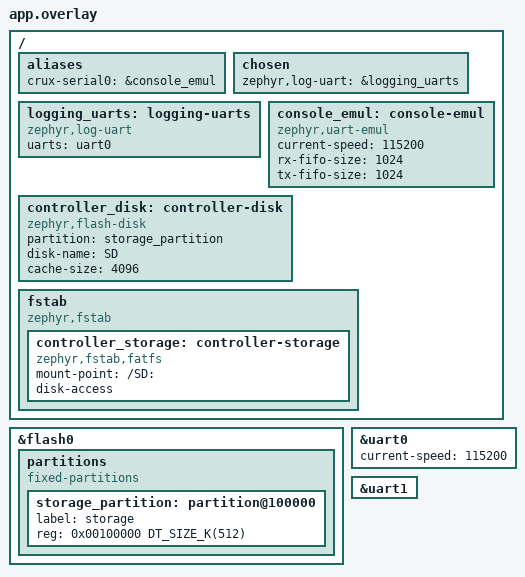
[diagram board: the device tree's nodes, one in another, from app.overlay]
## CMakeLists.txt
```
# SPDX-License-Identifier: Apache-2.0

# The base image on native_sim for a person at the host: HTTPS management on the host's loopback
# address, Crux Logging on standard output and the Crux serial console on a pseudo-terminal
# (docs/native-sim-interactive.md). It is built as a product builds the base image: the framework is
# the Zephyr module of this repository, turned on by CONFIG_CRUX_CONTROLLER_FRAMEWORK, and this file
# names no source or include directory of the framework. It is for development only. The entropy is
# the simulator's test source, so a key made here protects nothing, and the build refuses any other
# board; a board image of the framework includes framework/management/entropy.cmake, which refuses a
# test source.

cmake_minimum_required(VERSION 3.20.0)
find_package(Zephyr REQUIRED HINTS $ENV{ZEPHYR_BASE})
project(controller_framework_interactive_native_sim LANGUAGES C)

if(NOT CONFIG_BOARD_NATIVE_SIM OR NOT CONFIG_FAKE_ENTROPY_NATIVE_SIM)
    message(FATAL_ERROR "The interactive configuration is for native_sim only: its entropy source is a test source")
endif()
if(NOT CONFIG_CRUX_WEB_BIND_ADDRESS STREQUAL "127.0.0.1")
    message(FATAL_ERROR "The interactive configuration listens on the host's loopback address only: "
                        "CONFIG_CRUX_WEB_BIND_ADDRESS must be \"127.0.0.1\"")
endif()
if(NOT CONFIG_CRUX_CONTROLLER_FRAMEWORK OR NOT CONFIG_CRUX_CONTROLLER_FRAMEWORK_MANAGEMENT
   OR NOT CONFIG_CRUX_CONTROLLER_FRAMEWORK_CLI_SERIAL)
    message(FATAL_ERROR "The interactive configuration needs the framework with web management and the serial command line")
endif()

# Interim, development only: native_sim's offload reports a client's FIN so that a close without a TLS
# close_notify does not spin the web server (nsos_rdhup.cmake, docs/native-sim-interactive.md).
include(${CMAKE_CURRENT_LIST_DIR}/nsos_rdhup.cmake)

target_sources(app PRIVATE src/interactive.c)
target_link_libraries(app PRIVATE controller::framework)
controller_framework_image()
```

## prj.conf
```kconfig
# The base image on native_sim for a person at the host (docs/native-sim-interactive.md). The values
# are those of the base scenario (tests/framework/base/prj.conf) with these changes:
#   - the network is the host's, through native_sim's offloaded sockets, in place of Zephyr's
#     loopback interface, and management listens on the host's 127.0.0.1 port 8443;
#   - Crux Logging writes to native_sim's first PTY UART, which is the program's standard output;
#   - the store is a FAT volume on the flash simulator, which keeps its contents in a host file;
#   - no Ztest and no emulated log UART;
#   - the main thread runs the start function below the supervisor, as app/conf/base.conf sets, and a
#     restart request restarts the program. There is no retained region.
# For development only: the entropy is the simulator's test source.
CONFIG_CRUX_CONTROLLER_FRAMEWORK=y
CONFIG_SNTP=y
# No SNTP server answers there, so time synchronisation starts and its queries fail; nothing leaves
# the host.
CONFIG_CRUX_CONTROLLER_TIME_SERVER="127.0.0.1"

# Health supervision in the production watchdog configuration of the base image: no task watchdog
# hardware fallback, no start without a watchdog, no fault injection. native_sim has no watchdog
# behind the alias crux-watchdog0 here, so the watchdog is not armed and the controller is degraded.
# There is no retained region, so the boot counter lives in RAM. A restart request, from the command
# line or from the supervisor, restarts the program (CONFIG_NATIVE_SIM_REBOOT).
CONFIG_TASK_WDT=y
CONFIG_TASK_WDT_HW_FALLBACK=n
CONFIG_CRUX_REBOOT=y
CONFIG_NATIVE_SIM_REBOOT=y
CONFIG_MAIN_THREAD_PRIORITY=8

# The Crux serial console runs on an emulated UART, the only kind that Crux Serial accepts on
# native_sim; src/interactive.c bridges it to the second PTY UART.
CONFIG_CRUX_SERIAL=y
CONFIG_CRUX_CLI=y
CONFIG_CRUX_CLI_CONSOLE=y
CONFIG_CRUX_CLI_CONSOLE_PRIORITY=11
CONFIG_UART_INTERRUPT_DRIVEN=y
CONFIG_UART_USE_RUNTIME_CONFIGURE=y
CONFIG_EMUL=y
CONFIG_UART_EMUL=y

CONFIG_STD_C17=y
# The web adapter refuses the external libc of native_sim, as in the base scenario.
CONFIG_PICOLIBC=y
CONFIG_MAIN_STACK_SIZE=32768
CONFIG_HEAP_MEM_POOL_SIZE=32768

# The Mbed TLS profile of app/conf/base.conf, with the heap of the base image (no TLS client runs in
# this process).
CONFIG_MBEDTLS=y
CONFIG_MBEDTLS_PSA_CRYPTO_C=y
CONFIG_PSA_CRYPTO_PROVIDER_MBEDTLS=y
CONFIG_MBEDTLS_ENABLE_HEAP=y
CONFIG_MBEDTLS_HEAP_SIZE=120000
CONFIG_MBEDTLS_SSL_IN_CONTENT_LEN=16384
CONFIG_MBEDTLS_SSL_OUT_CONTENT_LEN=16384
CONFIG_MBEDTLS_SSL_PROTO_TLS1_2=y
CONFIG_MBEDTLS_SSL_PROTO_TLS1_3=y
CONFIG_MBEDTLS_SSL_TLS1_3_KEY_EXCHANGE_MODE_EPHEMERAL_ENABLED=y
CONFIG_MBEDTLS_KEY_EXCHANGE_ECDHE_ECDSA_ENABLED=y
CONFIG_MBEDTLS_CIPHERSUITE_TLS_ECDHE_ECDSA_WITH_AES_128_GCM_SHA256=y
CONFIG_MBEDTLS_CIPHERSUITE_TLS1_3_AES_128_GCM_SHA256=y
CONFIG_PSA_WANT_ALG_SHA_256=y
CONFIG_PSA_WANT_ECC_SECP_R1_256=y
CONFIG_PSA_WANT_ALG_ECDSA=y
CONFIG_PSA_WANT_ALG_ECDH=y
CONFIG_PSA_WANT_ALG_GCM=y
CONFIG_PSA_WANT_KEY_TYPE_AES=y
CONFIG_PSA_WANT_ALG_HMAC=y
CONFIG_PSA_WANT_KEY_TYPE_HMAC=y
CONFIG_PSA_WANT_ALG_HKDF=y
CONFIG_PSA_WANT_ALG_PBKDF2_HMAC=y
CONFIG_PSA_WANT_ALG_TLS12_PRF=y
CONFIG_PSA_WANT_KEY_TYPE_ECC_PUBLIC_KEY=y
CONFIG_PSA_WANT_KEY_TYPE_ECC_KEY_PAIR_IMPORT=y
CONFIG_PSA_WANT_KEY_TYPE_ECC_KEY_PAIR_EXPORT=y
CONFIG_PSA_WANT_KEY_TYPE_ECC_KEY_PAIR_GENERATE=y
CONFIG_PSA_WANT_KEY_TYPE_ECC_KEY_PAIR_DERIVE=y
CONFIG_MBEDTLS_PK_WRITE_C=y
CONFIG_CRUX_PSA_THREADING=y

CONFIG_CRUX_ACCESS=y
CONFIG_CRUX_CONFIG_SERVICE=y
CONFIG_CRUX_MGMT_STATUS=y
CONFIG_CRUX_TLS_CERTIFICATE=y
CONFIG_CRUX_WEB=y
CONFIG_CRUX_WEB_SESSION=y
CONFIG_CRUX_WEB_MANAGEMENT=y
CONFIG_CRUX_SYSTEM=y
CONFIG_CRUX_NETIF=y
CONFIG_WATCHDOG=y
CONFIG_HWINFO=y
CONFIG_REBOOT=y

# The host's loopback address only, and a port that needs no privilege on the host.
CONFIG_CRUX_WEB_PORT=8443
CONFIG_CRUX_WEB_BIND_ADDRESS="127.0.0.1"
CONFIG_CRUX_WEB_BACKLOG=4
CONFIG_HTTP_SERVER_MAX_CLIENTS=3
CONFIG_HTTP_SERVER_STACK_SIZE=16384
CONFIG_CRUX_WEB_SESSION_WORKER_PRIORITY=11
CONFIG_CRUX_WEB_MANAGEMENT_WORKER_PRIORITY=11
CONFIG_CRUX_SECURITY_EVENT_DRAIN_PRIORITY=11

# The simulator's fake entropy source: test-only, so nothing made here is a secret.
# scripts/run-native-sim.sh seeds it from the host for each run.
CONFIG_ENTROPY_GENERATOR=y

# Crux File on a flash disk of the flash simulator, which native_sim keeps in a host file (option
# --flash), so accounts, settings, the key and the certificate outlive a restart. The zone formats
# the blank disk at the first start.
CONFIG_FILE_SYSTEM=y
CONFIG_FILE_SYSTEM_MKFS=y
CONFIG_FAT_FILESYSTEM_ELM=y
CONFIG_FS_FATFS_LFN=y
CONFIG_FS_FATFS_LFN_MODE_STACK=y
CONFIG_FS_FATFS_MAX_LFN=127
CONFIG_FS_FATFS_MOUNT_MKFS=n
CONFIG_FS_FATFS_REENTRANT=y
CONFIG_FS_FATFS_NUM_FILES=6
CONFIG_DISK_DRIVERS=y
CONFIG_DISK_DRIVER_FLASH=y
CONFIG_CRUX_FILE_FATFS_SIMULATOR=y

# The network: the host's sockets through native_sim's offloaded sockets driver, with Zephyr's TLS
# socket layer on top. No TAP interface and no loopback interface of Zephyr.
CONFIG_NETWORKING=y
CONFIG_NET_IPV4=y
CONFIG_NET_IPV6=n
CONFIG_NET_TCP=y
CONFIG_NET_UDP=y
CONFIG_NET_SOCKETS=y
CONFIG_NET_DRIVERS=y
CONFIG_NET_SOCKETS_OFFLOAD=y
CONFIG_NET_NATIVE_OFFLOADED_SOCKETS=y
CONFIG_ETH_NATIVE_TAP=n
CONFIG_NET_SOCKETS_SOCKOPT_TLS=y
CONFIG_TLS_CREDENTIALS=y
CONFIG_TLS_MAX_CREDENTIALS_NUMBER=4
CONFIG_NET_SOCKETS_TLS_MAX_CONTEXTS=6
CONFIG_ZVFS_OPEN_MAX=48
CONFIG_ZVFS_POLL_MAX=24
CONFIG_ZVFS_EVENTFD=y
CONFIG_NET_MAX_CONTEXTS=32
CONFIG_NET_MAX_CONN=32

# Crux Logging on native_sim's console UART, as Crux's logging contract describes it, connected to
# the program's standard output.
CONFIG_CRUX_LOGGING=y
CONFIG_SERIAL=y
CONFIG_CONSOLE=y
CONFIG_UART_CONSOLE=y
CONFIG_UART_NATIVE_PTY_0_ON_STDINOUT=y
CONFIG_STDOUT_CONSOLE=n
CONFIG_EARLY_CONSOLE=n
CONFIG_CONSOLE_HANDLER=n
CONFIG_CONSOLE_SUBSYS=n
CONFIG_LOG=y
CONFIG_LOG_MODE_DEFERRED=y
CONFIG_LOG_MODE_OVERFLOW=n
CONFIG_LOG_BLOCK_IN_THREAD=n
CONFIG_LOG_PROCESS_THREAD=y
CONFIG_LOG_PROCESS_THREAD_STACK_SIZE=2048
CONFIG_LOG_PROCESS_THREAD_CUSTOM_PRIORITY=y
CONFIG_LOG_PROCESS_THREAD_PRIORITY=14
CONFIG_LOG_BUFFER_SIZE=8192
CONFIG_LOG_MAX_LEVEL=4
CONFIG_LOG_DEFAULT_LEVEL=0
CONFIG_LOG_RUNTIME_FILTERING=n
CONFIG_LOG_BACKEND_UART=y
CONFIG_LOG_BACKEND_NATIVE_POSIX=n
CONFIG_LOG_BACKEND_UART_ASYNC=n
CONFIG_LOG_PRINTK=y
CONFIG_SHELL_LOG_BACKEND=n
CONFIG_LOG_BACKEND_SHOW_LEVEL=y
CONFIG_LOG_BACKEND_CRLF_NONE=n
CONFIG_BOOT_BANNER=n
CONFIG_THREAD_MONITOR=y
CONFIG_THREAD_NAME=y
# An image with Crux management must not enable the Zephyr shell.
CONFIG_SHELL=n
```

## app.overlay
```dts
/* SPDX-License-Identifier: Apache-2.0 */
/* The devicetree of the interactive configuration (docs/native-sim-interactive.md).
 *
 * - Crux Logging writes to native_sim's console UART, uart0, which prj.conf connects to the
 *   program's standard output (Crux's logging contract names this composition).
 * - The Crux serial console owns an emulated UART through the alias crux-serial0, because Crux
 *   Serial accepts only an emulated UART on native_sim. src/interactive.c bridges it to uart1, a PTY UART
 *   that native_sim connects to a new pseudo-terminal of the host.
 * - The store is a FAT volume on a flash disk of the flash simulator, which native_sim keeps in a
 *   host file. The fstab entry is controller_storage, the name that the composition zone looks up.
 *   The partition and the disk are those of Crux's management composition on native_sim
 *   (tests/native/management_composition/app.overlay at the pinned Crux). */
/delete-node/ &storage_partition;

&flash0 {
    partitions {
        compatible = "fixed-partitions";
        #address-cells = <1>;
        #size-cells = <1>;

        storage_partition: partition@100000 {
            label = "storage";
            reg = <0x00100000 DT_SIZE_K(512)>;
        };
    };
};

&uart0 { current-speed = <115200>; };
&uart1 { status = "okay"; };

/ {
    aliases { crux-serial0 = &console_emul; };
    chosen { zephyr,log-uart = &logging_uarts; };
    logging_uarts: logging-uarts {
        compatible = "zephyr,log-uart";
        uarts = <&uart0>;
    };
    console_emul: console-emul {
        compatible = "zephyr,uart-emul";
        current-speed = <115200>;
        rx-fifo-size = <1024>;
        tx-fifo-size = <1024>;
        status = "okay";
    };

    controller_disk: controller-disk {
        compatible = "zephyr,flash-disk";
        partition = <&storage_partition>;
        disk-name = "SD";
        cache-size = <4096>;
        status = "okay";
    };

    fstab {
        compatible = "zephyr,fstab";
        controller_storage: controller-storage {
            compatible = "zephyr,fstab,fatfs";
            mount-point = "/SD:";
            disk-access;
        };
    };
};
```

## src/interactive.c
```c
/* SPDX-License-Identifier: Apache-2.0 */

/* The base image on native_sim for a person at the host (docs/native-sim-interactive.md): main
 * starts the controller framework as the base image does, and a bridge thread connects the Crux
 * serial console to a pseudo-terminal of the host.
 *
 * The bridge exists because Crux Serial accepts only an emulated UART on native_sim (the
 * BUILD_ASSERT in components/serial/ports/zephyr/serial_binding.c at the pinned Crux), while a
 * person needs a pseudo-terminal. It copies what the person types on the PTY UART uart1 into the
 * receive side of the emulated UART, and what the console writes on the emulated UART to uart1. It
 * polls both, because the PTY UART reads without blocking. Development only: a board image has no
 * bridge, and the console owns its UART there. */

#include <stddef.h>
#include <stdint.h>

#include <controller/framework.h>
#include <zephyr/device.h>
#include <zephyr/drivers/serial/uart_emul.h>
#include <zephyr/drivers/uart.h>
#include <zephyr/kernel.h>
#include <zephyr/sys/printk.h>

#define CONSOLE_EMUL DEVICE_DT_GET(DT_ALIAS(crux_serial0))
#define CONSOLE_PTY DEVICE_DT_GET(DT_NODELABEL(uart1))
#define BRIDGE_POLL_MS 5
#define BRIDGE_CHUNK 64u
#define BRIDGE_STACK 2048
/* Below the console (CONFIG_CRUX_CLI_CONSOLE_PRIORITY) and the web workers, above the log. */
#define BRIDGE_PRIORITY 13

/* Typed bytes into the emulated UART. A full receive FIFO is retried, so a paste is kept. */
static void bridge_typed(void)
{
    uint8_t chunk[BRIDGE_CHUNK];
    unsigned char byte;
    size_t length = 0u;

    while (length < sizeof chunk && uart_poll_in(CONSOLE_PTY, &byte) == 0) {
        chunk[length++] = byte;
    }
    for (size_t done = 0u; done < length;) {
        done += uart_emul_put_rx_data(CONSOLE_EMUL, &chunk[done], length - done);
        if (done < length) {
            k_msleep(BRIDGE_POLL_MS);
        }
    }
}

/* The console's output to the pseudo-terminal. */
static void bridge_written(void)
{
    uint8_t chunk[BRIDGE_CHUNK];
    uint32_t got;

    while ((got = uart_emul_get_tx_data(CONSOLE_EMUL, chunk, sizeof chunk)) > 0u) {
        for (uint32_t i = 0u; i < got; i++) {
            uart_poll_out(CONSOLE_PTY, chunk[i]);
        }
    }
}

static void bridge_run(void *unused1, void *unused2, void *unused3)
{
    ARG_UNUSED(unused1);
    ARG_UNUSED(unused2);
    ARG_UNUSED(unused3);

    if (!device_is_ready(CONSOLE_EMUL) || !device_is_ready(CONSOLE_PTY)) {
        printk("console bridge: a UART is not ready\n");
        return;
    }
    for (;;) {
        bridge_typed();
        bridge_written();
        k_msleep(BRIDGE_POLL_MS);
    }
}

K_THREAD_DEFINE(console_bridge, BRIDGE_STACK, bridge_run, NULL, NULL, NULL, BRIDGE_PRIORITY, 0, 0);

int main(void)
{
    return controller_framework_start(NULL) == CONTROLLER_FRAMEWORK_OK ? 0 : -1;
}
```
